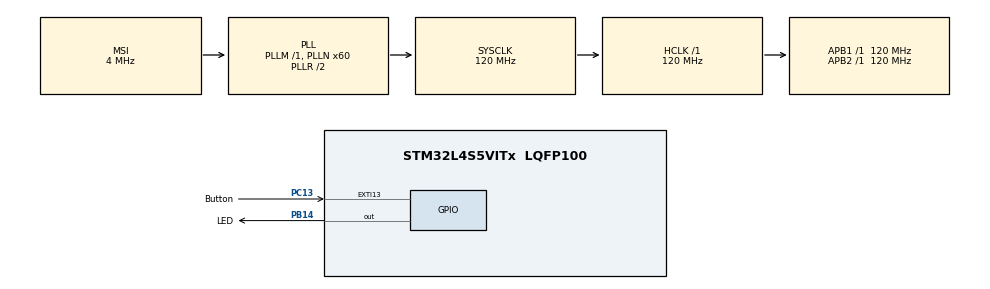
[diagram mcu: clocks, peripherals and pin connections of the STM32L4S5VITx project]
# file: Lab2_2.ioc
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ADC1.Channel-1\#ChannelRegularConversion=ADC_CHANNEL_TEMPSENSOR
ADC1.NbrOfConversionFlag=1
ADC1.OffsetNumber-1\#ChannelRegularConversion=ADC_OFFSET_NONE
ADC1.Rank-1\#ChannelRegularConversion=1
ADC1.Resolution=ADC_RESOLUTION_16B
ADC1.SamplingTime-1\#ChannelRegularConversion=ADC_SAMPLETIME_2CYCLES_5
ADC1.master=1
Mcu.Family=STM32L4
Mcu.Name=STM32L4S5VITx
Mcu.Package=LQFP100
NVIC.EXTI15_10_IRQn=true\:0\:0\:false\:false\:true\:true\:true\:true
NVIC.PriorityGroup=NVIC_PRIORITYGROUP_4
PB14.GPIO_Label=LED
PB14.Signal=GPIO_Output
PC13.GPIO_Label=Button
PC13.Signal=GPXTI13
ProjectManager.HeapSize=0x200
ProjectManager.StackSize=0x400
ProjectManager.TargetToolchain=STM32CubeIDE
RCC.ADCFreq_Value=48000000
RCC.AHBFreq_Value=120000000
RCC.APB1Freq_Value=120000000
RCC.APB1TimFreq_Value=120000000
RCC.APB2Freq_Value=120000000
RCC.APB2TimFreq_Value=120000000
RCC.CortexFreq_Value=120000000
RCC.HCLKFreq_Value=120000000
RCC.HSE_VALUE=8000000
RCC.HSI48_VALUE=48000000
RCC.HSI_VALUE=16000000
RCC.LSE_VALUE=32768
RCC.MSI_VALUE=4000000
RCC.PLLN=60
RCC.PLLSAI1N=24
RCC.SYSCLKFreq_VALUE=120000000
RCC.SYSCLKSource=RCC_SYSCLKSOURCE_PLLCLK
RCC.USBFreq_Value=48000000
RCC.VCOOutputFreq_Value=240000000
VP_ADC1_TempSens_Input.Mode=IN-TempSens
board=B-L4S5I-IOT01A

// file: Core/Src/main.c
/* USER CODE BEGIN Header */
/**
  ******************************************************************************
  * @file           : main.c
  * @brief          : Main program body
  ******************************************************************************
  * @attention
  *
  * Copyright (c) 2024 STMicroelectronics.
  * All rights reserved.
  *
  * This software is licensed under terms that can be found in the LICENSE file
  * in the root directory of this software component.
  * If no LICENSE file comes with this software, it is provided AS-IS.
  *
  ******************************************************************************
  */
/* USER CODE END Header */
#include "main.h"
#include <stdbool.h>

ADC_HandleTypeDef hadc1;

/* USER CODE BEGIN PV */
bool LEDState;
float output;
int32_t rawVoltage;
float VREF;
float temp;
/* USER CODE END PV */

void SystemClock_Config(void);
static void MX_GPIO_Init(void);
//static void MX_ADC1_Init(void);

/* USER CODE BEGIN 0 */

//This is the interrupt function that is called when the button is pressed
void HAL_GPIO_EXTI_Callback(uint16_t GPIO_Pin)
{
	LEDState = !LEDState;
	HAL_GPIO_WritePin(LED_GPIO_Port, LED_Pin, LEDState);
}

/* USER CODE END 0 */

static void MX_ADC1_Init(void)
{

/** Common config
*/
	hadc1.Instance = ADC1;
	hadc1.Init.ClockPrescaler = ADC_CLOCK_ASYNC_DIV1;
	hadc1.Init.Resolution = ADC_RESOLUTION_12B;
	hadc1.Init.DataAlign = ADC_DATAALIGN_RIGHT;
	hadc1.Init.ScanConvMode = ADC_SCAN_DISABLE;
	hadc1.Init.EOCSelection = ADC_EOC_SINGLE_CONV;
	hadc1.Init.LowPowerAutoWait = DISABLE;
	hadc1.Init.ContinuousConvMode = DISABLE;
	hadc1.Init.NbrOfConversion = 1;
	hadc1.Init.DiscontinuousConvMode = DISABLE;
	hadc1.Init.ExternalTrigConv = ADC_SOFTWARE_START;
	hadc1.Init.ExternalTrigConvEdge = ADC_EXTERNALTRIGCONVEDGE_NONE;
	hadc1.Init.DMAContinuousRequests = DISABLE;
	hadc1.Init.Overrun = ADC_OVR_DATA_PRESERVED;
	hadc1.Init.OversamplingMode = DISABLE;
	if (HAL_ADC_Init(&hadc1) != HAL_OK)
	{
		Error_Handler();
	}

/** Configure Regular Channel
*/

}
int main(void)
{

	ADC_ChannelConfTypeDef sConfig;

  /* MCU Configuration--------------------------------------------------------*/

  /* Reset of all peripherals, Initializes the Flash interface and the Systick. */
  HAL_Init();

  /* Configure the system clock */
  SystemClock_Config();

  /* Initialize all configured peripherals */
  MX_GPIO_Init();
  MX_ADC1_Init();
  while(HAL_ADCEx_Calibration_Start(&hadc1, ADC_SINGLE_ENDED) != HAL_OK);

  /* Infinite loop */
  /* USER CODE BEGIN WHILE */
  sConfig.Rank = ADC_REGULAR_RANK_1;
  sConfig.OffsetNumber = ADC_OFFSET_NONE;
  sConfig.Offset = 0;
  sConfig.SingleDiff = ADC_SINGLE_ENDED;
  while (1)
  {
    /* USER CODE END WHILE */

    /* USER CODE BEGIN 3 */
	  if (LEDState){
		  sConfig.Channel = ADC_CHANNEL_TEMPSENSOR;
		  sConfig.SamplingTime = ADC_SAMPLETIME_6CYCLES_5;

		  HAL_ADC_ConfigChannel(&hadc1, &sConfig);
		  HAL_ADC_Start(&hadc1);
		  while(HAL_ADC_PollForConversion(&hadc1, 1000000) != HAL_OK);
		  uint16_t TS_Data = HAL_ADC_GetValue(&hadc1);
		  float calibratedTS_Data = (float) TS_Data;
		  calibratedTS_Data = calibratedTS_Data*(VREF/3.0); //scale ADC data according to reference voltage

		  //get calibration data from memory
		  int32_t TS_CAL2 = (int32_t) *((uint16_t *) 0x1FFF75CA);
		  int32_t TS_CAL1 = (int32_t) *((uint16_t *) 0x1FFF75A8);
		  //temperatures at which calibration data was collected according to Datasheet
		  int TS_CAL2_TEMP = 130;
		  int TS_CAL1_TEMP = 30;

		  //calculate avgSlope
		  float avgSlope = (TS_CAL2 - TS_CAL1)/(TS_CAL2_TEMP - TS_CAL1_TEMP);
		  //calculate temperature in Celsius
		  temp = (calibratedTS_Data - TS_CAL1)/avgSlope + 30.0f;
		  output = temp;

	  }else{
		  sConfig.Channel = ADC_CHANNEL_VREFINT;

		  sConfig.SamplingTime = ADC_SAMPLETIME_2CYCLES_5;

		  if (HAL_ADC_ConfigChannel(&hadc1, &sConfig) != HAL_OK) Error_Handler();

		  HAL_ADC_Start(&hadc1);
		  if(HAL_ADC_PollForConversion(&hadc1, 1000000) == HAL_OK){
			  int32_t ADCValue = (int32_t) HAL_ADC_GetValue(&hadc1);
			  int32_t VREFINT_CAL =(int32_t) *((uint16_t *) 0x1FFF75AA); //the calibration value
			  float VREF_Charac = 3.0; //voltage characterized at VREFINT during manufacturing, specified in datasheet
			  VREF = VREF_Charac*((float) VREFINT_CAL/ADCValue); //calculate VREF
			  output = VREF;
		  }
	  }
  }
  /* USER CODE END 3 */
}

void SystemClock_Config(void)
{
  RCC_OscInitTypeDef RCC_OscInitStruct = {0};
  RCC_ClkInitTypeDef RCC_ClkInitStruct = {0};

  /** Configure the main internal regulator output voltage
  */
  if (HAL_PWREx_ControlVoltageScaling(PWR_REGULATOR_VOLTAGE_SCALE1_BOOST) != HAL_OK)
  {
    Error_Handler();
  }

  /** Initializes the RCC Oscillators according to the specified parameters
  * in the RCC_OscInitTypeDef structure.
  */
  RCC_OscInitStruct.OscillatorType = RCC_OSCILLATORTYPE_MSI;
  RCC_OscInitStruct.MSIState = RCC_MSI_ON;
  RCC_OscInitStruct.MSICalibrationValue = 0;
  RCC_OscInitStruct.MSIClockRange = RCC_MSIRANGE_6;
  RCC_OscInitStruct.PLL.PLLState = RCC_PLL_ON;
  RCC_OscInitStruct.PLL.PLLSource = RCC_PLLSOURCE_MSI;
  RCC_OscInitStruct.PLL.PLLM = 1;
  RCC_OscInitStruct.PLL.PLLN = 60;
  RCC_OscInitStruct.PLL.PLLP = RCC_PLLP_DIV2;
  RCC_OscInitStruct.PLL.PLLQ = RCC_PLLQ_DIV2;
  RCC_OscInitStruct.PLL.PLLR = RCC_PLLR_DIV2;
  if (HAL_RCC_OscConfig(&RCC_OscInitStruct) != HAL_OK)
  {
    Error_Handler();
  }

  /** Initializes the CPU, AHB and APB buses clocks
  */
  RCC_ClkInitStruct.ClockType = RCC_CLOCKTYPE_HCLK|RCC_CLOCKTYPE_SYSCLK
                              |RCC_CLOCKTYPE_PCLK1|RCC_CLOCKTYPE_PCLK2;
  RCC_ClkInitStruct.SYSCLKSource = RCC_SYSCLKSOURCE_PLLCLK;
  RCC_ClkInitStruct.AHBCLKDivider = RCC_SYSCLK_DIV1;
  RCC_ClkInitStruct.APB1CLKDivider = RCC_HCLK_DIV1;
  RCC_ClkInitStruct.APB2CLKDivider = RCC_HCLK_DIV1;

  if (HAL_RCC_ClockConfig(&RCC_ClkInitStruct, FLASH_LATENCY_5) != HAL_OK)
  {
    Error_Handler();
  }
}

static void MX_GPIO_Init(void)
{
  GPIO_InitTypeDef GPIO_InitStruct = {0};

  /* GPIO Ports Clock Enable */
  __HAL_RCC_GPIOC_CLK_ENABLE();
  __HAL_RCC_GPIOB_CLK_ENABLE();

  /*Configure GPIO pin Output Level */
  HAL_GPIO_WritePin(LED_GPIO_Port, LED_Pin, GPIO_PIN_RESET);

  /*Configure GPIO pin : Button_Pin */
  GPIO_InitStruct.Pin = Button_Pin;
  GPIO_InitStruct.Mode = GPIO_MODE_IT_RISING;
  GPIO_InitStruct.Pull = GPIO_NOPULL;
  HAL_GPIO_Init(Button_GPIO_Port, &GPIO_InitStruct);

  /*Configure GPIO pin : LED_Pin */
  GPIO_InitStruct.Pin = LED_Pin;
  GPIO_InitStruct.Mode = GPIO_MODE_OUTPUT_PP;
  GPIO_InitStruct.Pull = GPIO_NOPULL;
  GPIO_InitStruct.Speed = GPIO_SPEED_FREQ_LOW;
  HAL_GPIO_Init(LED_GPIO_Port, &GPIO_InitStruct);

  /* EXTI interrupt init*/
  HAL_NVIC_SetPriority(EXTI15_10_IRQn, 0, 0);
  HAL_NVIC_EnableIRQ(EXTI15_10_IRQn);

}

void Error_Handler(void)
{
  __disable_irq();
  while (1)
  {
  }
}
